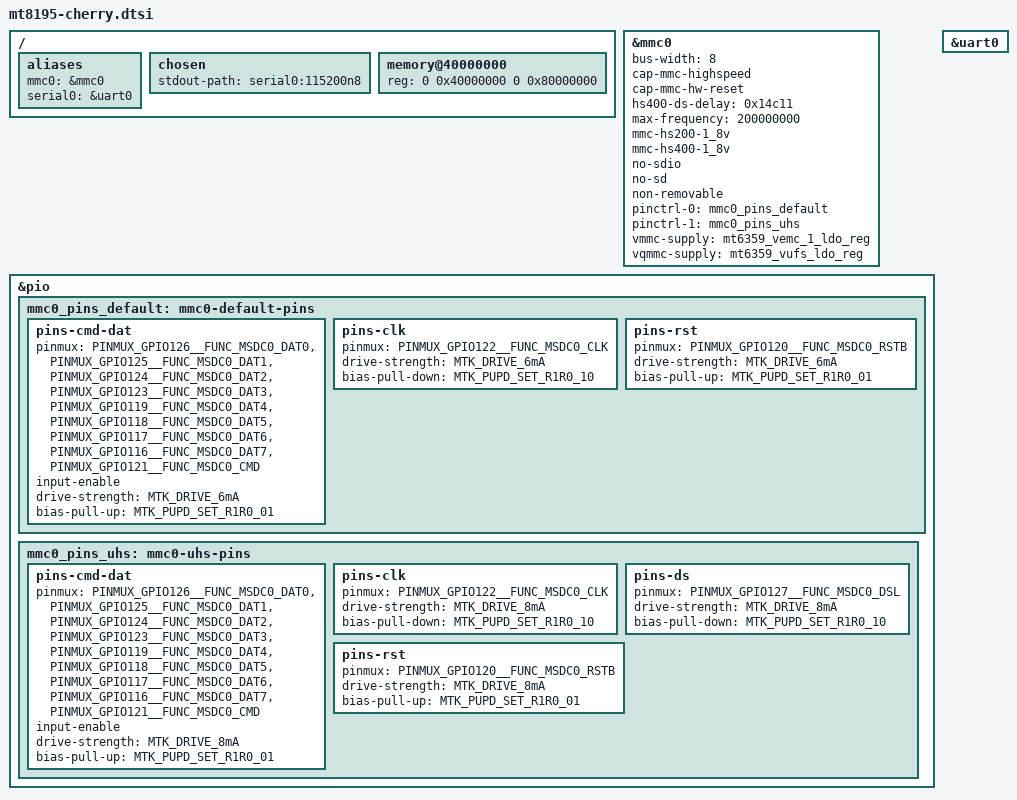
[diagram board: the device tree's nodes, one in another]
// SPDX-License-Identifier: (GPL-2.0 OR MIT)
/*
 * Copyright (C) 2021 MediaTek Inc.
 */

#include <dt-bindings/gpio/gpio.h>
#include "mt8195.dtsi"
#include "mt6359.dtsi"

/ {
	aliases {
		mmc0 = &mmc0;
		serial0 = &uart0;
	};

	chosen {
		stdout-path = "serial0:115200n8";
	};

	memory@40000000 {
		device_type = "memory";
		reg = <0 0x40000000 0 0x80000000>;
	};
};

&mmc0 {
	status = "okay";

	bus-width = <8>;
	cap-mmc-highspeed;
	cap-mmc-hw-reset;
	hs400-ds-delay = <0x14c11>;
	max-frequency = <200000000>;
	mmc-hs200-1_8v;
	mmc-hs400-1_8v;
	no-sdio;
	no-sd;
	non-removable;
	pinctrl-names = "default", "state_uhs";
	pinctrl-0 = <&mmc0_pins_default>;
	pinctrl-1 = <&mmc0_pins_uhs>;
	vmmc-supply = <&mt6359_vemc_1_ldo_reg>;
	vqmmc-supply = <&mt6359_vufs_ldo_reg>;
};

&pio {
	mmc0_pins_default: mmc0-default-pins {
		pins-cmd-dat {
			pinmux = <PINMUX_GPIO126__FUNC_MSDC0_DAT0>,
				 <PINMUX_GPIO125__FUNC_MSDC0_DAT1>,
				 <PINMUX_GPIO124__FUNC_MSDC0_DAT2>,
				 <PINMUX_GPIO123__FUNC_MSDC0_DAT3>,
				 <PINMUX_GPIO119__FUNC_MSDC0_DAT4>,
				 <PINMUX_GPIO118__FUNC_MSDC0_DAT5>,
				 <PINMUX_GPIO117__FUNC_MSDC0_DAT6>,
				 <PINMUX_GPIO116__FUNC_MSDC0_DAT7>,
				 <PINMUX_GPIO121__FUNC_MSDC0_CMD>;
			input-enable;
			drive-strength = <MTK_DRIVE_6mA>;
			bias-pull-up = <MTK_PUPD_SET_R1R0_01>;
		};

		pins-clk {
			pinmux = <PINMUX_GPIO122__FUNC_MSDC0_CLK>;
			drive-strength = <MTK_DRIVE_6mA>;
			bias-pull-down = <MTK_PUPD_SET_R1R0_10>;
		};

		pins-rst {
			pinmux = <PINMUX_GPIO120__FUNC_MSDC0_RSTB>;
			drive-strength = <MTK_DRIVE_6mA>;
			bias-pull-up = <MTK_PUPD_SET_R1R0_01>;
		};
	};

	mmc0_pins_uhs: mmc0-uhs-pins {
		pins-cmd-dat {
			pinmux = <PINMUX_GPIO126__FUNC_MSDC0_DAT0>,
				 <PINMUX_GPIO125__FUNC_MSDC0_DAT1>,
				 <PINMUX_GPIO124__FUNC_MSDC0_DAT2>,
				 <PINMUX_GPIO123__FUNC_MSDC0_DAT3>,
				 <PINMUX_GPIO119__FUNC_MSDC0_DAT4>,
				 <PINMUX_GPIO118__FUNC_MSDC0_DAT5>,
				 <PINMUX_GPIO117__FUNC_MSDC0_DAT6>,
				 <PINMUX_GPIO116__FUNC_MSDC0_DAT7>,
				 <PINMUX_GPIO121__FUNC_MSDC0_CMD>;
			input-enable;
			drive-strength = <MTK_DRIVE_8mA>;
			bias-pull-up = <MTK_PUPD_SET_R1R0_01>;
		};

		pins-clk {
			pinmux = <PINMUX_GPIO122__FUNC_MSDC0_CLK>;
			drive-strength = <MTK_DRIVE_8mA>;
			bias-pull-down = <MTK_PUPD_SET_R1R0_10>;
		};

		pins-ds {
			pinmux = <PINMUX_GPIO127__FUNC_MSDC0_DSL>;
			drive-strength = <MTK_DRIVE_8mA>;
			bias-pull-down = <MTK_PUPD_SET_R1R0_10>;
		};

		pins-rst {
			pinmux = <PINMUX_GPIO120__FUNC_MSDC0_RSTB>;
			drive-strength = <MTK_DRIVE_8mA>;
			bias-pull-up = <MTK_PUPD_SET_R1R0_01>;
		};
	};
};

&uart0 {
	status = "okay";
};
